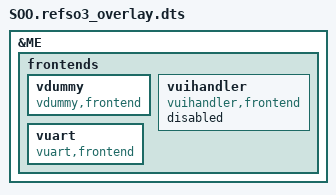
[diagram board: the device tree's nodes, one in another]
/include/ "so3virt.dts"

&ME {
		
    frontends {
    
        vdummy {
            compatible = "vdummy,frontend";
            status = "ok";
        };

        vuihandler {
            compatible = "vuihandler,frontend";
            status = "disabled";
        };

        vuart {
            compatible = "vuart,frontend";
            status = "ok";
        };
    };
};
